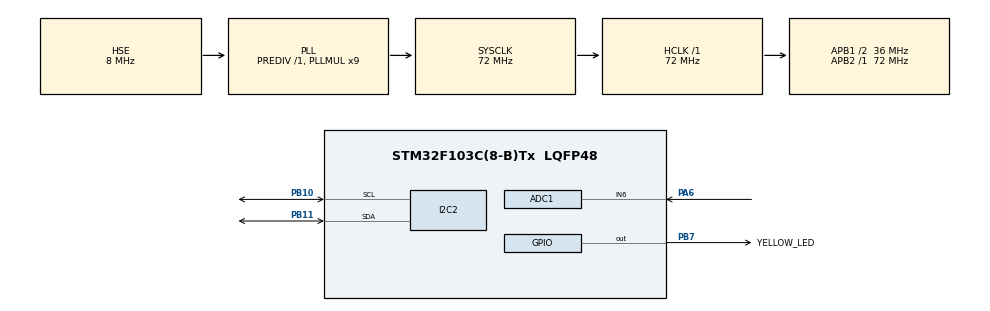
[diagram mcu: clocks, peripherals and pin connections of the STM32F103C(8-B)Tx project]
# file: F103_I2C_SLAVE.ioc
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ADC1.Channel-4\#ChannelRegularConversion=ADC_CHANNEL_6
ADC1.NbrOfConversionFlag=1
ADC1.Rank-4\#ChannelRegularConversion=1
ADC1.SamplingTime-4\#ChannelRegularConversion=ADC_SAMPLETIME_1CYCLE_5
ADC1.master=1
I2C2.I2C_Mode=I2C_Standard
I2C2.OwnAddress=0x4
Mcu.Family=STM32F1
Mcu.Name=STM32F103C(8-B)Tx
Mcu.Package=LQFP48
NVIC.PriorityGroup=NVIC_PRIORITYGROUP_4
PA13.Mode=Serial_Wire
PA13.Signal=SYS_JTMS-SWDIO
PA14.Mode=Serial_Wire
PA14.Signal=SYS_JTCK-SWCLK
PA6.Signal=ADCx_IN6
PB10.Mode=I2C
PB10.Signal=I2C2_SCL
PB11.Mode=I2C
PB11.Signal=I2C2_SDA
PB7.GPIO_Label=YELLOW_LED
PB7.Signal=GPIO_Output
PD0-OSC_IN.Mode=HSE-External-Oscillator
PD0-OSC_IN.Signal=RCC_OSC_IN
PD1-OSC_OUT.Mode=HSE-External-Oscillator
PD1-OSC_OUT.Signal=RCC_OSC_OUT
ProjectManager.HeapSize=0x200
ProjectManager.StackSize=0x400
ProjectManager.TargetToolchain=SW4STM32
RCC.ADCPresc=RCC_ADCPCLK2_DIV6
RCC.AHBFreq_Value=72000000
RCC.APB1CLKDivider=RCC_HCLK_DIV2
RCC.APB1Freq_Value=36000000
RCC.APB1TimFreq_Value=72000000
RCC.APB2Freq_Value=72000000
RCC.APB2TimFreq_Value=72000000
RCC.HCLKFreq_Value=72000000
RCC.PLLMUL=RCC_PLL_MUL9
RCC.PLLSourceVirtual=RCC_PLLSOURCE_HSE
RCC.SYSCLKFreq_VALUE=72000000
RCC.SYSCLKSource=RCC_SYSCLKSOURCE_PLLCLK
RCC.USBFreq_Value=72000000
SH.ADCx_IN6.0=ADC1_IN6,IN6
board=stm32f103-hal-i2c-two-boards-communication-slave

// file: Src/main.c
/* USER CODE BEGIN Header */
/**
  ******************************************************************************
  * @file           : main.c
  * @brief          : Main program body
  ******************************************************************************
  * @attention
  *
  * <h2><center>&copy; Copyright (c) 2019 STMicroelectronics.
  * All rights reserved.</center></h2>
  *
  * This software component is licensed by ST under BSD 3-Clause license,
  * the "License"; You may not use this file except in compliance with the
  * License. You may obtain a copy of the License at:
  *                        opensource.org/licenses/BSD-3-Clause
  *
  ******************************************************************************
  */
/* USER CODE END Header */

#include "main.h"

ADC_HandleTypeDef hadc1;

I2C_HandleTypeDef hi2c2;

/* USER CODE BEGIN PV */
#define MASTER_REQ_WRITE_LED	0x00
#define MASTER_REQ_READ_ADC     0x01

uint8_t transferRequest;
uint8_t ledValue;
uint16_t adcValue;
/* USER CODE END PV */

void SystemClock_Config(void);
static void MX_GPIO_Init(void);
static void MX_I2C2_Init(void);
static void MX_ADC1_Init(void);

int main(void)
{

  /* MCU Configuration--------------------------------------------------------*/

  /* Reset of all peripherals, Initializes the Flash interface and the Systick. */
  HAL_Init();

  /* Configure the system clock */
  SystemClock_Config();

  /* Initialize all configured peripherals */
  MX_GPIO_Init();
  MX_I2C2_Init();
  MX_ADC1_Init();

  /* Infinite loop */
  /* USER CODE BEGIN WHILE */
  while (1)
  {
	    while (HAL_I2C_Slave_Receive(&hi2c2, (uint8_t*)&transferRequest, 1, 10) != HAL_OK);
		/* Wait until I2C is ready */

	    while (HAL_I2C_GetState(&hi2c2) != HAL_I2C_STATE_READY);

		/* If master request write LED operation */
		if (transferRequest == MASTER_REQ_WRITE_LED)
	    {
		       /* Slave receives data from master */
		   while (HAL_I2C_Slave_Receive(&hi2c2, (uint8_t*)&ledValue, 1, 10) != HAL_OK);
			/* Wait until I2C is ready */
			while (HAL_I2C_GetState(&hi2c2) != HAL_I2C_STATE_READY);

			/* Turn on or off the LED depending on the command from master */
			if (ledValue)
			{
				HAL_GPIO_WritePin(YELLOW_LED_GPIO_Port, YELLOW_LED_Pin, GPIO_PIN_SET);
			}
			else
			{
				HAL_GPIO_WritePin(YELLOW_LED_GPIO_Port, YELLOW_LED_Pin, GPIO_PIN_RESET);
			}
	    }
			/* If master request read ADC operation */
		else if (transferRequest == MASTER_REQ_READ_ADC)
		{
			uint8_t tmpAdcValue[2];

			/* Enable ADC and start ADC conversion */
			HAL_ADC_Start(&hadc1);
			/* Wait for ADC conversion to be completed */
			HAL_ADC_PollForConversion(&hadc1, 1);
			/* Get ADC value from ADC data register */
			adcValue = HAL_ADC_GetValue(&hadc1);
			/* Stop ADC conversion and disable ADC */
			HAL_ADC_Stop(&hadc1);

			/* Split the ADC high and low value */
			/* Get ADC value from bit 0 to 7 */
			tmpAdcValue[0] = adcValue & 0xFF;
			/* Get ADC value from bit 8 to 11 */
			tmpAdcValue[1] = adcValue >> 8;

			/* Slave transmit ADC value to master */
	  while (HAL_I2C_Slave_Transmit(&hi2c2, (uint8_t*)tmpAdcValue, 2, 10) != HAL_OK);
			/* Wait until I2C is ready */
			while (HAL_I2C_GetState(&hi2c2) != HAL_I2C_STATE_READY);
		}
  }
  /* USER CODE END 3 */
}

void SystemClock_Config(void)
{
  RCC_OscInitTypeDef RCC_OscInitStruct = {0};
  RCC_ClkInitTypeDef RCC_ClkInitStruct = {0};
  RCC_PeriphCLKInitTypeDef PeriphClkInit = {0};

  /** Initializes the CPU, AHB and APB busses clocks
  */
  RCC_OscInitStruct.OscillatorType = RCC_OSCILLATORTYPE_HSE;
  RCC_OscInitStruct.HSEState = RCC_HSE_ON;
  RCC_OscInitStruct.HSEPredivValue = RCC_HSE_PREDIV_DIV1;
  RCC_OscInitStruct.HSIState = RCC_HSI_ON;
  RCC_OscInitStruct.PLL.PLLState = RCC_PLL_ON;
  RCC_OscInitStruct.PLL.PLLSource = RCC_PLLSOURCE_HSE;
  RCC_OscInitStruct.PLL.PLLMUL = RCC_PLL_MUL9;
  if (HAL_RCC_OscConfig(&RCC_OscInitStruct) != HAL_OK)
  {
    Error_Handler();
  }
  /** Initializes the CPU, AHB and APB busses clocks
  */
  RCC_ClkInitStruct.ClockType = RCC_CLOCKTYPE_HCLK|RCC_CLOCKTYPE_SYSCLK
                              |RCC_CLOCKTYPE_PCLK1|RCC_CLOCKTYPE_PCLK2;
  RCC_ClkInitStruct.SYSCLKSource = RCC_SYSCLKSOURCE_PLLCLK;
  RCC_ClkInitStruct.AHBCLKDivider = RCC_SYSCLK_DIV1;
  RCC_ClkInitStruct.APB1CLKDivider = RCC_HCLK_DIV2;
  RCC_ClkInitStruct.APB2CLKDivider = RCC_HCLK_DIV1;

  if (HAL_RCC_ClockConfig(&RCC_ClkInitStruct, FLASH_LATENCY_2) != HAL_OK)
  {
    Error_Handler();
  }
  PeriphClkInit.PeriphClockSelection = RCC_PERIPHCLK_ADC;
  PeriphClkInit.AdcClockSelection = RCC_ADCPCLK2_DIV6;
  if (HAL_RCCEx_PeriphCLKConfig(&PeriphClkInit) != HAL_OK)
  {
    Error_Handler();
  }
}

static void MX_ADC1_Init(void)
{

  ADC_ChannelConfTypeDef sConfig = {0};

  /** Common config
  */
  hadc1.Instance = ADC1;
  hadc1.Init.ScanConvMode = ADC_SCAN_DISABLE;
  hadc1.Init.ContinuousConvMode = DISABLE;
  hadc1.Init.DiscontinuousConvMode = DISABLE;
  hadc1.Init.ExternalTrigConv = ADC_SOFTWARE_START;
  hadc1.Init.DataAlign = ADC_DATAALIGN_RIGHT;
  hadc1.Init.NbrOfConversion = 1;
  if (HAL_ADC_Init(&hadc1) != HAL_OK)
  {
    Error_Handler();
  }
  /** Configure Regular Channel
  */
  sConfig.Channel = ADC_CHANNEL_6;
  sConfig.Rank = ADC_REGULAR_RANK_1;
  sConfig.SamplingTime = ADC_SAMPLETIME_1CYCLE_5;
  if (HAL_ADC_ConfigChannel(&hadc1, &sConfig) != HAL_OK)
  {
    Error_Handler();
  }

}

static void MX_I2C2_Init(void)
{

  hi2c2.Instance = I2C2;
  hi2c2.Init.ClockSpeed = 100000;
  hi2c2.Init.DutyCycle = I2C_DUTYCYCLE_2;
  hi2c2.Init.OwnAddress1 = 8;
  hi2c2.Init.AddressingMode = I2C_ADDRESSINGMODE_7BIT;
  hi2c2.Init.DualAddressMode = I2C_DUALADDRESS_DISABLE;
  hi2c2.Init.OwnAddress2 = 0;
  hi2c2.Init.GeneralCallMode = I2C_GENERALCALL_DISABLE;
  hi2c2.Init.NoStretchMode = I2C_NOSTRETCH_DISABLE;
  if (HAL_I2C_Init(&hi2c2) != HAL_OK)
  {
    Error_Handler();
  }

}

static void MX_GPIO_Init(void)
{
  GPIO_InitTypeDef GPIO_InitStruct = {0};

  /* GPIO Ports Clock Enable */
  __HAL_RCC_GPIOC_CLK_ENABLE();
  __HAL_RCC_GPIOD_CLK_ENABLE();
  __HAL_RCC_GPIOA_CLK_ENABLE();
  __HAL_RCC_GPIOB_CLK_ENABLE();

  /*Configure GPIO pin Output Level */
  HAL_GPIO_WritePin(YELLOW_LED_GPIO_Port, YELLOW_LED_Pin, GPIO_PIN_RESET);

  /*Configure GPIO pins : PC13 PC14 PC15 */
  GPIO_InitStruct.Pin = GPIO_PIN_13|GPIO_PIN_14|GPIO_PIN_15;
  GPIO_InitStruct.Mode = GPIO_MODE_ANALOG;
  HAL_GPIO_Init(GPIOC, &GPIO_InitStruct);

  /*Configure GPIO pins : PA0 PA1 PA2 PA3
                           PA4 PA5 PA7 PA8
                           PA9 PA10 PA11 PA12
                           PA15 */
  GPIO_InitStruct.Pin = GPIO_PIN_0|GPIO_PIN_1|GPIO_PIN_2|GPIO_PIN_3
                          |GPIO_PIN_4|GPIO_PIN_5|GPIO_PIN_7|GPIO_PIN_8
                          |GPIO_PIN_9|GPIO_PIN_10|GPIO_PIN_11|GPIO_PIN_12
                          |GPIO_PIN_15;
  GPIO_InitStruct.Mode = GPIO_MODE_ANALOG;
  HAL_GPIO_Init(GPIOA, &GPIO_InitStruct);

  /*Configure GPIO pins : PB0 PB1 PB2 PB12
                           PB13 PB14 PB15 PB3
                           PB4 PB5 PB6 PB8
                           PB9 */
  GPIO_InitStruct.Pin = GPIO_PIN_0|GPIO_PIN_1|GPIO_PIN_2|GPIO_PIN_12
                          |GPIO_PIN_13|GPIO_PIN_14|GPIO_PIN_15|GPIO_PIN_3
                          |GPIO_PIN_4|GPIO_PIN_5|GPIO_PIN_6|GPIO_PIN_8
                          |GPIO_PIN_9;
  GPIO_InitStruct.Mode = GPIO_MODE_ANALOG;
  HAL_GPIO_Init(GPIOB, &GPIO_InitStruct);

  /*Configure GPIO pin : YELLOW_LED_Pin */
  GPIO_InitStruct.Pin = YELLOW_LED_Pin;
  GPIO_InitStruct.Mode = GPIO_MODE_OUTPUT_PP;
  GPIO_InitStruct.Pull = GPIO_NOPULL;
  GPIO_InitStruct.Speed = GPIO_SPEED_FREQ_LOW;
  HAL_GPIO_Init(YELLOW_LED_GPIO_Port, &GPIO_InitStruct);

}

void Error_Handler(void)
{
}

/************************ (C) COPYRIGHT STMicroelectronics *****END OF FILE****/
